AUTOSAR XML (schema 4-3-0)
standard types defined: UINT8, UINT16, UINT32, UINT64, SINT8, SINT16, SINT32, FLOAT32, FLOAT64
package /Pkg_ErrorMgrAgg_1_0_B/ComponentTypes
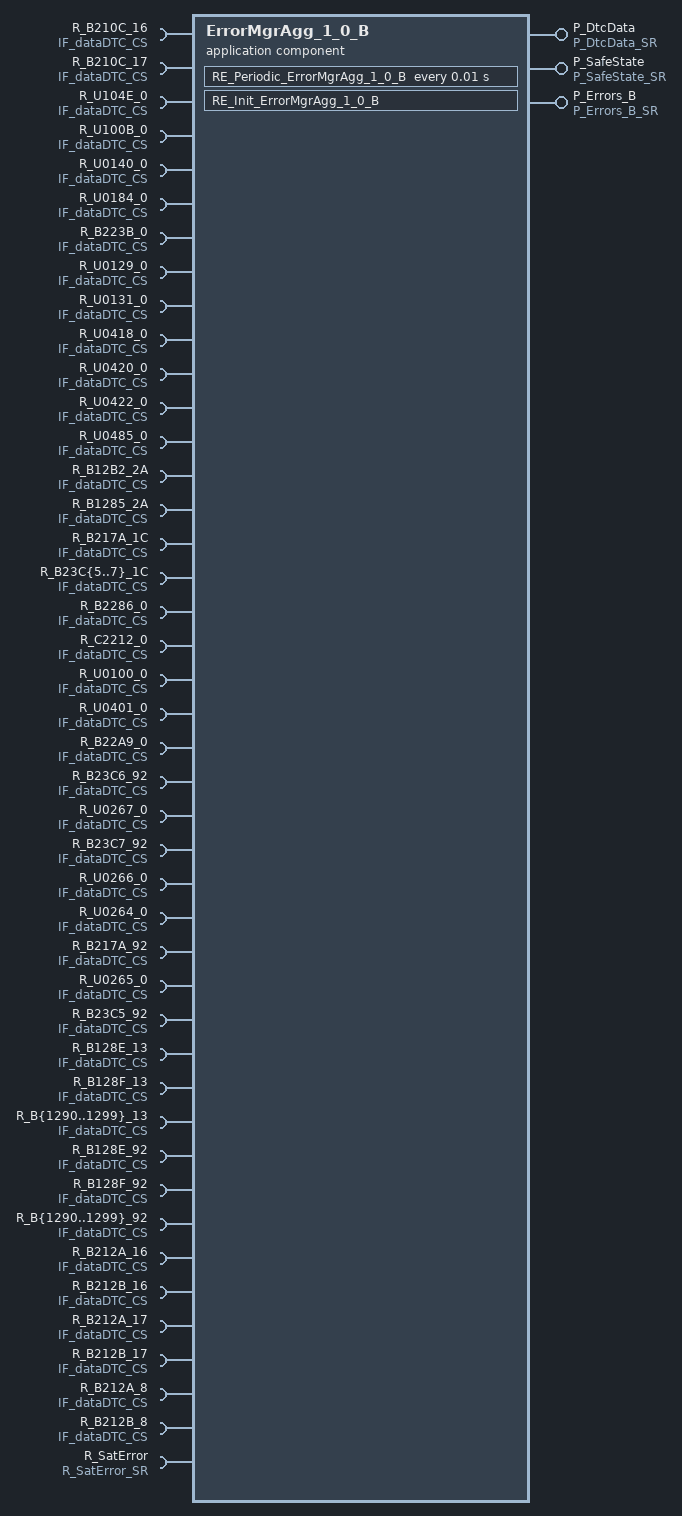
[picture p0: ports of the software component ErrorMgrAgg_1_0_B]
  application sw component type ErrorMgrAgg_1_0_B
    provide port P_DtcData: provided-interface=P_DtcData_SR
      provided-com-specs:
        data-element=Data_DtcStatus_B, init-value=constant-reference=init_Data_DtcStatus_B
        data-element=Data_DtcAddData_B, init-value=constant-reference=init_Data_DtcAddData_B
    provide port P_SafeState: nonqueued-sender-com-spec{data-element=SafeStateOp, init-value=constant-reference=init_SafeStateOp}, provided-interface=P_SafeState_SR
    provide port P_Errors_B: nonqueued-sender-com-spec=data-element=Errors_B, provided-interface=P_Errors_B_SR
    63 x require port:
      R_B210C_16: client-com-spec=dTCinfo_v, required-interface=IF_dataDTC_CS
      R_B210C_17: client-com-spec=dTCinfo_v, required-interface=IF_dataDTC_CS
      R_U104E_0: client-com-spec=dTCinfo_v, required-interface=IF_dataDTC_CS
      R_U100B_0: client-com-spec=dTCinfo_v, required-interface=IF_dataDTC_CS
      R_U0140_0: client-com-spec=dTCinfo_v, required-interface=IF_dataDTC_CS
      R_U0184_0: client-com-spec=dTCinfo_v, required-interface=IF_dataDTC_CS
      R_B223B_0: client-com-spec=dTCinfo_v, required-interface=IF_dataDTC_CS
      R_U0129_0: client-com-spec=dTCinfo_v, required-interface=IF_dataDTC_CS
      R_U0131_0: client-com-spec=dTCinfo_v, required-interface=IF_dataDTC_CS
      R_U0418_0: client-com-spec=dTCinfo_v, required-interface=IF_dataDTC_CS
      R_U0420_0: client-com-spec=dTCinfo_v, required-interface=IF_dataDTC_CS
      R_U0422_0: client-com-spec=dTCinfo_v, required-interface=IF_dataDTC_CS
      R_U0485_0: client-com-spec=dTCinfo_v, required-interface=IF_dataDTC_CS
      R_B12B2_2A: client-com-spec=dTCinfo_v, required-interface=IF_dataDTC_CS
      R_B1285_2A: client-com-spec=dTCinfo_v, required-interface=IF_dataDTC_CS
      R_B217A_1C: client-com-spec=dTCinfo_v, required-interface=IF_dataDTC_CS
      R_B23C{5..7}_1C: client-com-spec=dTCinfo_v, required-interface=IF_dataDTC_CS
      R_B2286_0: client-com-spec=dTCinfo_v, required-interface=IF_dataDTC_CS
      R_C2212_0: client-com-spec=dTCinfo_v, required-interface=IF_dataDTC_CS
      R_U0100_0: client-com-spec=dTCinfo_v, required-interface=IF_dataDTC_CS
      R_U0401_0: client-com-spec=dTCinfo_v, required-interface=IF_dataDTC_CS
      R_B22A9_0: client-com-spec=dTCinfo_v, required-interface=IF_dataDTC_CS
      R_B23C6_92: client-com-spec=dTCinfo_v, required-interface=IF_dataDTC_CS
      R_U0267_0: client-com-spec=dTCinfo_v, required-interface=IF_dataDTC_CS
      R_B23C7_92: client-com-spec=dTCinfo_v, required-interface=IF_dataDTC_CS
      R_U0266_0: client-com-spec=dTCinfo_v, required-interface=IF_dataDTC_CS
      R_U0264_0: client-com-spec=dTCinfo_v, required-interface=IF_dataDTC_CS
      R_B217A_92: client-com-spec=dTCinfo_v, required-interface=IF_dataDTC_CS
      R_U0265_0: client-com-spec=dTCinfo_v, required-interface=IF_dataDTC_CS
      R_B23C5_92: client-com-spec=dTCinfo_v, required-interface=IF_dataDTC_CS
      R_B128E_13: client-com-spec=dTCinfo_v, required-interface=IF_dataDTC_CS
      R_B128F_13: client-com-spec=dTCinfo_v, required-interface=IF_dataDTC_CS
      R_B{1290..1299}_13: client-com-spec=dTCinfo_v, required-interface=IF_dataDTC_CS
      R_B128E_92: client-com-spec=dTCinfo_v, required-interface=IF_dataDTC_CS
      R_B128F_92: client-com-spec=dTCinfo_v, required-interface=IF_dataDTC_CS
      R_B{1290..1299}_92: client-com-spec=dTCinfo_v, required-interface=IF_dataDTC_CS
      R_B212A_16: client-com-spec=dTCinfo_v, required-interface=IF_dataDTC_CS
      R_B212B_16: client-com-spec=dTCinfo_v, required-interface=IF_dataDTC_CS
      R_B212A_17: client-com-spec=dTCinfo_v, required-interface=IF_dataDTC_CS
      R_B212B_17: client-com-spec=dTCinfo_v, required-interface=IF_dataDTC_CS
      R_B212A_8: client-com-spec=dTCinfo_v, required-interface=IF_dataDTC_CS
      R_B212B_8: client-com-spec=dTCinfo_v, required-interface=IF_dataDTC_CS
      R_SatError: required-interface=R_SatError_SR
        required-com-specs:
          data-element=Data_ErrorMgr_ErrorCommPack_1_0_B, init-value=constant-reference=init_Data_ErrorMgr_ErrorCommPack_1_0_B
          data-element=Data_ErrorMgr_ErrorCommPack_2_0_B, init-value=constant-reference=init_Data_ErrorMgr_ErrorCommPack_2_0_B
          data-element=Data_ErrorMgr_ErrorCommPack_2_1_B, init-value=constant-reference=init_Data_ErrorMgr_ErrorCommPack_2_1_B
          data-element=Data_ErrorMgr_ErrorCommPack_QNX_B, init-value=constant-reference=init_Data_ErrorMgr_ErrorCommPack_QNX_B
    behavior ErrorMgrAgg_1_0_B_InternalBehavior: handle-termination-and-restart=NO-SUPPORT
      timing event TMT_RE_Periodic_ErrorMgrAgg_1_0_B: start-on-event=RE_Periodic_ErrorMgrAgg_1_0_B, period=0.01
      init event InitEvent: start-on-event=RE_Init_ErrorMgrAgg_1_0_B
      port-api-options:
        enable-take-address=false, indirect-api=false, port=P_DtcData
        enable-take-address=false, indirect-api=false, port=P_Errors_B
        enable-take-address=false, indirect-api=false, port=P_SafeState
        enable-take-address=false, indirect-api=false, port=R_B1285_2A
        enable-take-address=false, indirect-api=false, port=R_B128E_13
        enable-take-address=false, indirect-api=false, port=R_B128E_92
        enable-take-address=false, indirect-api=false, port=R_B128F_13
        enable-take-address=false, indirect-api=false, port=R_B128F_92
        enable-take-address=false, indirect-api=false, port=R_B1290_13
        enable-take-address=false, indirect-api=false, port=R_B1290_92
        enable-take-address=false, indirect-api=false, port=R_B1291_13
        enable-take-address=false, indirect-api=false, port=R_B1291_92
        enable-take-address=false, indirect-api=false, port=R_B1292_13
        enable-take-address=false, indirect-api=false, port=R_B1292_92
        enable-take-address=false, indirect-api=false, port=R_B1293_13
        enable-take-address=false, indirect-api=false, port=R_B1293_92
        enable-take-address=false, indirect-api=false, port=R_B1294_13
        enable-take-address=false, indirect-api=false, port=R_B1294_92
        enable-take-address=false, indirect-api=false, port=R_B1295_13
        enable-take-address=false, indirect-api=false, port=R_B1295_92
        enable-take-address=false, indirect-api=false, port=R_B1296_13
        enable-take-address=false, indirect-api=false, port=R_B1296_92
        enable-take-address=false, indirect-api=false, port=R_B1297_13
        enable-take-address=false, indirect-api=false, port=R_B1297_92
        enable-take-address=false, indirect-api=false, port=R_B1298_13
        enable-take-address=false, indirect-api=false, port=R_B1298_92
        enable-take-address=false, indirect-api=false, port=R_B1299_13
        enable-take-address=false, indirect-api=false, port=R_B1299_92
        enable-take-address=false, indirect-api=false, port=R_B12B2_2A
        enable-take-address=false, indirect-api=false, port=R_B210C_16
        enable-take-address=false, indirect-api=false, port=R_B210C_17
        enable-take-address=false, indirect-api=false, port=R_B212A_16
        enable-take-address=false, indirect-api=false, port=R_B212A_17
        enable-take-address=false, indirect-api=false, port=R_B212A_8
        enable-take-address=false, indirect-api=false, port=R_B212B_16
        enable-take-address=false, indirect-api=false, port=R_B212B_17
        enable-take-address=false, indirect-api=false, port=R_B212B_8
        enable-take-address=false, indirect-api=false, port=R_B217A_1C
        enable-take-address=false, indirect-api=false, port=R_B217A_92
        enable-take-address=false, indirect-api=false, port=R_B223B_0
        enable-take-address=false, indirect-api=false, port=R_B2286_0
        enable-take-address=false, indirect-api=false, port=R_B22A9_0
        enable-take-address=false, indirect-api=false, port=R_B23C5_1C
        enable-take-address=false, indirect-api=false, port=R_B23C5_92
        enable-take-address=false, indirect-api=false, port=R_B23C6_1C
        enable-take-address=false, indirect-api=false, port=R_B23C6_92
        enable-take-address=false, indirect-api=false, port=R_B23C7_1C
        enable-take-address=false, indirect-api=false, port=R_B23C7_92
        enable-take-address=false, indirect-api=false, port=R_C2212_0
        enable-take-address=false, indirect-api=false, port=R_SatError
        enable-take-address=false, indirect-api=false, port=R_U0100_0
        enable-take-address=false, indirect-api=false, port=R_U0129_0
        enable-take-address=false, indirect-api=false, port=R_U0131_0
        enable-take-address=false, indirect-api=false, port=R_U0140_0
        enable-take-address=false, indirect-api=false, port=R_U0184_0
        enable-take-address=false, indirect-api=false, port=R_U{0264..0267}_0
        enable-take-address=false, indirect-api=false, port=R_U0401_0
        enable-take-address=false, indirect-api=false, port=R_U0418_0
        enable-take-address=false, indirect-api=false, port=R_U0420_0
        enable-take-address=false, indirect-api=false, port=R_U0422_0
        enable-take-address=false, indirect-api=false, port=R_U0485_0
        enable-take-address=false, indirect-api=false, port=R_U100B_0
        enable-take-address=false, indirect-api=false, port=R_U104E_0
      runnable RE_Periodic_ErrorMgrAgg_1_0_B  # Periodic Runnable of Satellite
        data-receive-point-by-arguments:
          4 x access:
            REC_R_SatError_Data_ErrorMgr_ErrorCommPack_1_0_B: accessed-variable=R_SatError.Data_ErrorMgr_ErrorCommPack_1_0_B
            REC_R_SatError_Data_ErrorMgr_ErrorCommPack_2_0_B: accessed-variable=R_SatError.Data_ErrorMgr_ErrorCommPack_2_0_B
            REC_R_SatError_Data_ErrorMgr_ErrorCommPack_2_1_B: accessed-variable=R_SatError.Data_ErrorMgr_ErrorCommPack_2_1_B
            REC_R_SatError_Data_ErrorMgr_ErrorCommPack_QNX_B: accessed-variable=R_SatError.Data_ErrorMgr_ErrorCommPack_QNX_B
        data-send-points:
          4 x access:
            SEND_P_DtcData_Data_DtcStatus_B: accessed-variable=P_DtcData.Data_DtcStatus_B
            SEND_P_DtcData_Data_DtcAddData_B: accessed-variable=P_DtcData.Data_DtcAddData_B
            SEND_P_SafeState_SafeStateOp: accessed-variable=P_SafeState.SafeStateOp
            SEND_P_Errors_B_Errors_B: accessed-variable=P_Errors_B.Errors_B
        62 x sync call, all with timeout=0:
          SC_R_B210C_16_dTCinfo_v: operation=R_B210C_16.dTCinfo_v
          SC_R_B210C_17_dTCinfo_v: operation=R_B210C_17.dTCinfo_v
          SC_R_U104E_0_dTCinfo_v: operation=R_U104E_0.dTCinfo_v
          SC_R_U100B_0_dTCinfo_v: operation=R_U100B_0.dTCinfo_v
          SC_R_U0140_0_dTCinfo_v: operation=R_U0140_0.dTCinfo_v
          SC_R_U0184_0_dTCinfo_v: operation=R_U0184_0.dTCinfo_v
          SC_R_B223B_0_dTCinfo_v: operation=R_B223B_0.dTCinfo_v
          SC_R_U0129_0_dTCinfo_v: operation=R_U0129_0.dTCinfo_v
          SC_R_U0131_0_dTCinfo_v: operation=R_U0131_0.dTCinfo_v
          SC_R_U0418_0_dTCinfo_v: operation=R_U0418_0.dTCinfo_v
          SC_R_U0420_0_dTCinfo_v: operation=R_U0420_0.dTCinfo_v
          SC_R_U0422_0_dTCinfo_v: operation=R_U0422_0.dTCinfo_v
          SC_R_U0485_0_dTCinfo_v: operation=R_U0485_0.dTCinfo_v
          SC_R_B12B2_2A_dTCinfo_v: operation=R_B12B2_2A.dTCinfo_v
          SC_R_B1285_2A_dTCinfo_v: operation=R_B1285_2A.dTCinfo_v
          SC_R_B217A_1C_dTCinfo_v: operation=R_B217A_1C.dTCinfo_v
          SC_R_B23C{5..7}_1C_dTCinfo_v: operation=R_B23C{5..7}_1C.dTCinfo_v
          SC_R_B2286_0_dTCinfo_v: operation=R_B2286_0.dTCinfo_v
          SC_R_C2212_0_dTCinfo_v: operation=R_C2212_0.dTCinfo_v
          SC_R_U0100_0_dTCinfo_v: operation=R_U0100_0.dTCinfo_v
          SC_R_U0401_0_dTCinfo_v: operation=R_U0401_0.dTCinfo_v
          SC_R_B22A9_0_dTCinfo_v: operation=R_B22A9_0.dTCinfo_v
          SC_R_B23C6_92_dTCinfo_v: operation=R_B23C6_92.dTCinfo_v
          SC_R_U0267_0_dTCinfo_v: operation=R_U0267_0.dTCinfo_v
          SC_R_B23C7_92_dTCinfo_v: operation=R_B23C7_92.dTCinfo_v
          SC_R_U0266_0_dTCinfo_v: operation=R_U0266_0.dTCinfo_v
          SC_R_U0264_0_dTCinfo_v: operation=R_U0264_0.dTCinfo_v
          SC_R_B217A_92_dTCinfo_v: operation=R_B217A_92.dTCinfo_v
          SC_R_U0265_0_dTCinfo_v: operation=R_U0265_0.dTCinfo_v
          SC_R_B23C5_92_dTCinfo_v: operation=R_B23C5_92.dTCinfo_v
          SC_R_B128E_13_dTCinfo_v: operation=R_B128E_13.dTCinfo_v
          SC_R_B128F_13_dTCinfo_v: operation=R_B128F_13.dTCinfo_v
          SC_R_B{1290..1299}_13_dTCinfo_v: operation=R_B{1290..1299}_13.dTCinfo_v
          SC_R_B128E_92_dTCinfo_v: operation=R_B128E_92.dTCinfo_v
          SC_R_B128F_92_dTCinfo_v: operation=R_B128F_92.dTCinfo_v
          SC_R_B{1290..1299}_92_dTCinfo_v: operation=R_B{1290..1299}_92.dTCinfo_v
          SC_R_B212A_16_dTCinfo_v: operation=R_B212A_16.dTCinfo_v
          SC_R_B212B_16_dTCinfo_v: operation=R_B212B_16.dTCinfo_v
          SC_R_B212A_17_dTCinfo_v: operation=R_B212A_17.dTCinfo_v
          SC_R_B212B_17_dTCinfo_v: operation=R_B212B_17.dTCinfo_v
          SC_R_B212A_8_dTCinfo_v: operation=R_B212A_8.dTCinfo_v
          SC_R_B212B_8_dTCinfo_v: operation=R_B212B_8.dTCinfo_v
      runnable RE_Init_ErrorMgrAgg_1_0_B  # Init Runnable
  swc implementation ErrorMgrAgg_1_0_B_Implementation: programming-language=C, vendor-id=0, behavior=ErrorMgrAgg_1_0_B_InternalBehavior
    code-descriptors:
      code Default: artifact-descriptors=autosar-engineering-object={short-label=Default, category=SWSRC}
package /Pkg_ErrorMgrAgg_1_0_B/Constant
  8 x constant specification:
    init_Data_DtcStatus_B: value-spec=fields=[0, 0, 0, 0, 0, 0, 0, 0, 0, 0, 0, 0, 0, 0, 0, 0, 0, 0, 0, 0, 0, 0, 0, 0, 0, 0, 0, 0, 0, 0, 0, 0, 0, 0, 0, 0, 0, 0, 0, 0, 0, 0, 0, 0, 0, 0, 0, 0, 0, 0, 0, 0, 0, 0, 0, 0, 0, 0, 0, 0, 0, 0]
    init_Data_DtcAddData_B: value-spec=fields=[[0, 0, 0, 0], [0, 0, 0, 0], [0, 0, 0, 0], [0, 0, 0, 0], [0, 0, 0, 0], [0, 0, 0, 0], [0, 0, 0, 0], [0, 0, 0, 0], [0, 0, 0, 0], [0, 0, 0, 0], [0, 0, 0, 0], [0, 0, 0, 0], [0, 0, 0, 0], [0, 0, 0, 0], [0, 0, 0, 0], [0, 0, 0, 0], [0, 0, 0, 0], [0, 0, 0, 0], [0, 0, 0, 0], [0, 0, 0, 0], [0, 0, 0, 0], [0, 0, 0, 0], [0, 0, 0, 0], [0, 0, 0, 0], [0, 0, 0, 0], [0, 0, 0, 0], [0, 0, 0, 0], [0, 0, 0, 0], [0, 0, 0, 0], [0, 0, 0, 0], [0, 0, 0, 0], [0, 0, 0, 0], [0, 0, 0, 0], [0, 0, 0, 0], [0, 0, 0, 0], [0, 0, 0, 0], [0, 0, 0, 0], [0, 0, 0, 0], [0, 0, 0, 0], [0, 0, 0, 0], [0, 0, 0, 0], [0, 0, 0, 0], [0, 0, 0, 0], [0, 0, 0, 0], [0, 0, 0, 0], [0, 0, 0, 0], [0, 0, 0, 0], [0, 0, 0, 0], [0, 0, 0, 0], [0, 0, 0, 0], [0, 0, 0, 0], [0, 0, 0, 0], [0, 0, 0, 0], [0, 0, 0, 0], [0, 0, 0, 0], [0, 0, 0, 0], [0, 0, 0, 0], [0, 0, 0, 0], [0, 0, 0, 0], [0, 0, 0, 0], [0, 0, 0, 0], [0, 0, 0, 0]]
    init_SafeStateOp: value-spec=fields=16 x 0
    init_Errors_B: value-spec=35 x 0
    init_Data_ErrorMgr_ErrorCommPack_1_0_B: value-spec=fields=[0, 0, 400 x 0, 400 x fields=[0, 0, 0, 0]]
    init_Data_ErrorMgr_ErrorCommPack_2_0_B: value-spec=fields=[0, 0, 144 x 0, 144 x fields=[0, 0, 0, 0]]
    init_Data_ErrorMgr_ErrorCommPack_2_1_B: value-spec=fields=[0, 0, 548 x 0, 548 x fields=[0, 0, 0, 0]]
    init_Data_ErrorMgr_ErrorCommPack_QNX_B: value-spec=fields=[0, 0, 8 x 0, 8 x fields=[0, 0, 0, 0]]
package /Pkg_ErrorMgrAgg_1_0_B/ImplementationDataTypes
  34 x impl type, all with type-emitter=RTE:
    BOOL: implementation-data-type=boolean
    ErrorMgr_ErrorField: implementation-data-type=uint8
    Error1_0QM_arr: category=ARRAY
      element Elem_ErrorMgr_ErrorField: array-size=12, array-size-semantics=FIXED-SIZE, implementation-data-type=ErrorMgr_ErrorField
    Data1_0QM_arr: category=ARRAY
      element Elem_ErrorMgr_stAddData: array-size=12, array-size-semantics=FIXED-SIZE, implementation-data-type=ErrorMgr_stAddData
    Error1_0B_arr: category=ARRAY
      element Elem_ErrorMgr_ErrorField: array-size=400, array-size-semantics=FIXED-SIZE, implementation-data-type=ErrorMgr_ErrorField
    Data1_0B_arr: category=ARRAY
      element Elem_ErrorMgr_stAddData: array-size=400, array-size-semantics=FIXED-SIZE, implementation-data-type=ErrorMgr_stAddData
    Error2_0QM_arr: category=ARRAY
      element Elem_ErrorMgr_ErrorField: array-size=1, array-size-semantics=FIXED-SIZE, implementation-data-type=ErrorMgr_ErrorField
    Padding2_0QM_arr: category=ARRAY
      element Elem_ErrorMgr_ErrorField: array-size=3, array-size-semantics=FIXED-SIZE, implementation-data-type=ErrorMgr_ErrorField
    Data2_0QM_arr: category=ARRAY
      element Elem_ErrorMgr_stAddData: array-size=1, array-size-semantics=FIXED-SIZE, implementation-data-type=ErrorMgr_stAddData
    Error2_0B_arr: category=ARRAY
      element Elem_ErrorMgr_ErrorField: array-size=144, array-size-semantics=FIXED-SIZE, implementation-data-type=ErrorMgr_ErrorField
    Data2_0B_arr: category=ARRAY
      element Elem_ErrorMgr_stAddData: array-size=144, array-size-semantics=FIXED-SIZE, implementation-data-type=ErrorMgr_stAddData
    Error2_1QM_arr: category=ARRAY
      element Elem_ErrorMgr_ErrorField: array-size=1, array-size-semantics=FIXED-SIZE, implementation-data-type=ErrorMgr_ErrorField
    Padding2_1QM_arr: category=ARRAY
      element Elem_ErrorMgr_ErrorField: array-size=3, array-size-semantics=FIXED-SIZE, implementation-data-type=ErrorMgr_ErrorField
    Data2_1QM_arr: category=ARRAY
      element Elem_ErrorMgr_stAddData: array-size=1, array-size-semantics=FIXED-SIZE, implementation-data-type=ErrorMgr_stAddData
    Error2_1B_arr: category=ARRAY
      element Elem_ErrorMgr_ErrorField: array-size=548, array-size-semantics=FIXED-SIZE, implementation-data-type=ErrorMgr_ErrorField
    Data2_1B_arr: category=ARRAY
      element Elem_ErrorMgr_stAddData: array-size=548, array-size-semantics=FIXED-SIZE, implementation-data-type=ErrorMgr_stAddData
    ErrorQNXQM_arr: category=ARRAY
      element Elem_ErrorMgr_ErrorField: array-size=1, array-size-semantics=FIXED-SIZE, implementation-data-type=ErrorMgr_ErrorField
    PaddingQNXQM_arr: category=ARRAY
      element Elem_ErrorMgr_ErrorField: array-size=3, array-size-semantics=FIXED-SIZE, implementation-data-type=ErrorMgr_ErrorField
    DataQNXQM_arr: category=ARRAY
      element Elem_ErrorMgr_stAddData: array-size=1, array-size-semantics=FIXED-SIZE, implementation-data-type=ErrorMgr_stAddData
    ErrorQNXB_arr: category=ARRAY
      element Elem_ErrorMgr_ErrorField: array-size=8, array-size-semantics=FIXED-SIZE, implementation-data-type=ErrorMgr_ErrorField
    DataQNXB_arr: category=ARRAY
      element Elem_ErrorMgr_stAddData: array-size=8, array-size-semantics=FIXED-SIZE, implementation-data-type=ErrorMgr_stAddData
    AdditionalData_arr: category=ARRAY
      element Elem_uint8: array-size=4, array-size-semantics=FIXED-SIZE, implementation-data-type=uint8
    SafeStateActive_arr: category=ARRAY
      element Elem_uint8: array-size=16, array-size-semantics=FIXED-SIZE, implementation-data-type=uint8
    ErrorListArr_B: category=ARRAY
      element Elem_uint32: array-size=35, array-size-semantics=FIXED-SIZE, implementation-data-type=uint32
    ErrorMgr_enSafeStates: compu {0=ErrorMgr_SafeState_safestate1, 1=ErrorMgr_SafeState_safestate16, 2=ErrorMgr_SafeState_safestate23, 3=ErrorMgr_SafeState_safestate24, 4=ErrorMgr_SafeState_safestate17, 5=ErrorMgr_SafeState_safestate13, 6=ErrorMgr_SafeState_safestate12, 7=ErrorMgr_SafeState_safestate9, 8=ErrorMgr_SafeState_safestate10, 9=ErrorMgr_SafeState_safestate7, 10=ErrorMgr_SafeState_safestate4, 11=ErrorMgr_SafeState_safestate2, 12=ErrorMgr_SafeState_safestate5, 13=ErrorMgr_SafeState_safestate11, 14=ErrorMgr_SafeState_safestate21, 15=ErrorMgr_SafeState_Max}, implementation-data-type=uint32
    ErrorMgr_enErrorStatus: compu {0=ErrorMgr_Invalid, 1=ErrorMgr_ErrorInactive, 2=ErrorMgr_ErrorActive}, implementation-data-type=uint32
    ErrorMgr_ErrorCommPack_1_0_B: category=STRUCTURE
      4 x element, all with category=TYPE_REFERENCE:
        RunningCounter: implementation-data-type=uint32
        Checksum: implementation-data-type=uint32
        Error: implementation-data-type=Error1_0B_arr
        Data: implementation-data-type=Data1_0B_arr
    ErrorMgr_ErrorCommPack_2_0_B: category=STRUCTURE
      4 x element, all with category=TYPE_REFERENCE:
        RunningCounter: implementation-data-type=uint32
        Checksum: implementation-data-type=uint32
        Error: implementation-data-type=Error2_0B_arr
        Data: implementation-data-type=Data2_0B_arr
    ErrorMgr_ErrorCommPack_2_1_B: category=STRUCTURE
      4 x element, all with category=TYPE_REFERENCE:
        RunningCounter: implementation-data-type=uint32
        Checksum: implementation-data-type=uint32
        Error: implementation-data-type=Error2_1B_arr
        Data: implementation-data-type=Data2_1B_arr
    ErrorMgr_ErrorCommPack_QNX_B: category=STRUCTURE
      4 x element, all with category=TYPE_REFERENCE:
        RunningCounter: implementation-data-type=uint32
        Checksum: implementation-data-type=uint32
        Error: implementation-data-type=ErrorQNXB_arr
        Data: implementation-data-type=DataQNXB_arr
    SafeStateOpDef: category=STRUCTURE
      element SafeStateActive: implementation-data-type=SafeStateActive_arr
    ErrorMgr_stAddData: category=STRUCTURE
      element AdditionalData: implementation-data-type=AdditionalData_arr
    DtcStatus_B: category=STRUCTURE
      62 x element, all with category=TYPE_REFERENCE, implementation-data-type=uint8:
        b210c_16_0
        b210c_17_0
        u104e_0_0
        u100b_0_0
        u0140_0_0
        u0184_0_0
        b223b_0_0
        u0129_0_0
        u0131_0_0
        u0418_0_0
        u0420_0_0
        u0422_0_0
        u0485_0_0
        b12b2_2a_0
        b1285_2a_0
        b128e_13_0
        b128f_13_0
        b{1290..1299}_13_0
        b128e_92_0
        b128f_92_0
        b{1290..1299}_92_0
        b212a_16_0
        b212b_16_0
        b22a9_0_0
        b23c6_92_0
        u0267_0_0
        b23c7_92_0
        u0266_0_0
        u0264_0_0
        b217a_92_0
        u0265_0_0
        b23c5_92_0
        b217a_1c_0
        b23c{5..7}_1c_0
        b2286_0_0
        c2212_0_0
        b212a_17_0
        b212b_17_0
        u0100_0_0
        u0401_0_0
        b212a_8_0
        b212b_8_0
    DtcAddData_B: category=STRUCTURE
      62 x element, all with category=TYPE_REFERENCE, implementation-data-type=AdditionalData_arr:
        b210c_16_0
        b210c_17_0
        u104e_0_0
        u100b_0_0
        u0140_0_0
        u0184_0_0
        b223b_0_0
        u0129_0_0
        u0131_0_0
        u0418_0_0
        u0420_0_0
        u0422_0_0
        u0485_0_0
        b12b2_2a_0
        b1285_2a_0
        b128e_13_0
        b128f_13_0
        b{1290..1299}_13_0
        b128e_92_0
        b128f_92_0
        b{1290..1299}_92_0
        b212a_16_0
        b212b_16_0
        b22a9_0_0
        b23c6_92_0
        u0267_0_0
        b23c7_92_0
        u0266_0_0
        u0264_0_0
        b217a_92_0
        u0265_0_0
        b23c5_92_0
        b217a_1c_0
        b23c{5..7}_1c_0
        b2286_0_0
        c2212_0_0
        b212a_17_0
        b212b_17_0
        u0100_0_0
        u0401_0_0
        b212a_8_0
        b212b_8_0
package /Pkg_ErrorMgrAgg_1_0_B/PortInterfaces
  4 x sender receiver interface:
    R_SatError_SR  # Comments
      4 x data:
        Data_ErrorMgr_ErrorCommPack_1_0_B: type=ErrorMgr_ErrorCommPack_1_0_B
        Data_ErrorMgr_ErrorCommPack_2_0_B: type=ErrorMgr_ErrorCommPack_2_0_B
        Data_ErrorMgr_ErrorCommPack_2_1_B: type=ErrorMgr_ErrorCommPack_2_1_B
        Data_ErrorMgr_ErrorCommPack_QNX_B: type=ErrorMgr_ErrorCommPack_QNX_B
    P_DtcData_SR  # Port for reading DTC Data
      data Data_DtcStatus_B: type=DtcStatus_B
      data Data_DtcAddData_B: type=DtcAddData_B
    P_SafeState_SR  # Safe State Outputs
      data SafeStateOp: type=SafeStateOpDef
    P_Errors_B_SR  # Status of Errors
      data Errors_B: type=ErrorListArr_B
